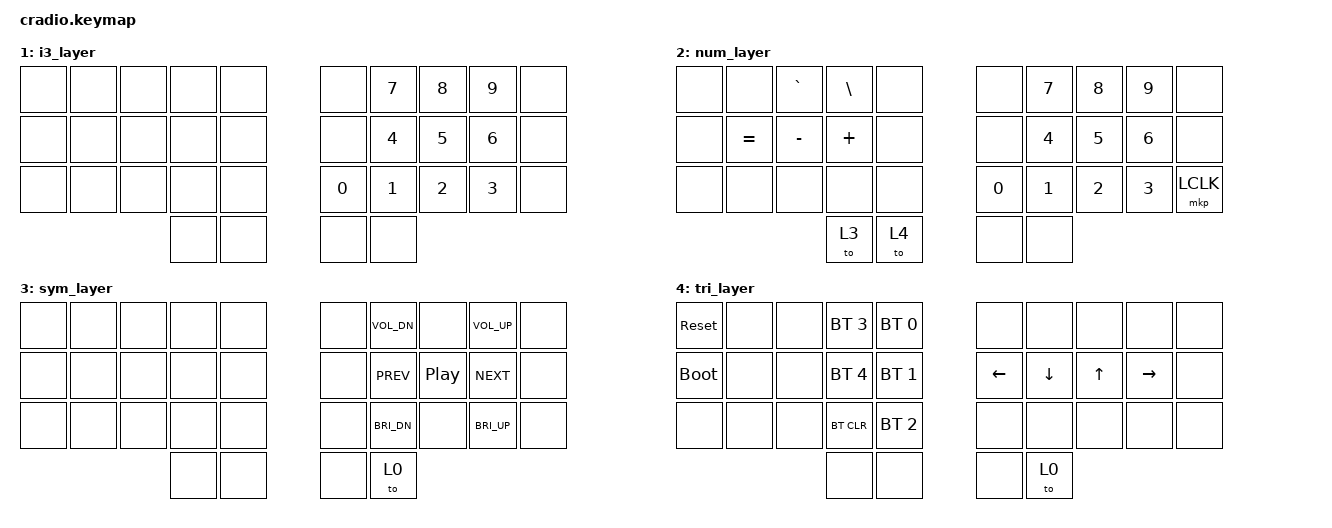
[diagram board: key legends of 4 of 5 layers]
// Copyright (c) 2022 The ZMK Contributors
// SPDX-License-Identifier: MIT

#include <behaviors.dtsi>
#include <dt-bindings/zmk/keys.h>
#include <dt-bindings/zmk/bt.h>
#include <dt-bindings/zmk/pointing.h>

// Home row mods macro
#define HRML(k1,k2,k3,k4) &ht LGUI k1  &ht LALT k2  &ht LSHFT k3  &ht LCTRL k4
#define HRMR(k1,k2,k3,k4) &ht RCTRL k1  &ht RSHFT k2  &ht RALT k3  &ht RGUI k4

/ {
    macros {
        /*
         * Layer-Mod macro:  &lm <layer> <modifier>
         *   – presses &mo <layer>  +  presses &kp <modifier>
         *   – releases both when the macro key is released
         */
        lm: lm {
            compatible = "zmk,behavior-macro-two-param";
            #binding-cells = <2>;
            wait-ms = <0>;
            tap-ms  = <0>;
            bindings =
                <&macro_param_1to1> , <&macro_press   &mo MACRO_PLACEHOLDER>,
                <&macro_param_2to1> , <&macro_press   &kp MACRO_PLACEHOLDER>,
                <&macro_pause_for_release>,
                <&macro_param_2to1> , <&macro_release &kp MACRO_PLACEHOLDER>,
                <&macro_param_1to1> , <&macro_release &mo MACRO_PLACEHOLDER>;
        };
    };

    behaviors {
        ht: hold_tap {
            compatible = "zmk,behavior-hold-tap";
            #binding-cells = <2>;
            flavor = "tap-preferred";
            tapping-term-ms = <200>;
            quick-tap-ms = <150>;
            require-prior-idle-ms = <125>;
            bindings = <&kp>, <&kp>;
        };
    };
    
    combos {
        compatible = "zmk,combos";
        combo_esc {
            timeout-ms = <30>;
          key-positions = <7 8>;
            bindings = <&kp ESC>;
        };
        combo_tab {
            timeout-ms = <30>;
            key-positions = <1 2>;
            bindings = <&kp TAB>;
        };
        combo_paren_l {
            timeout-ms = <30>;
            key-positions = <2 3>;
            bindings = <&kp LPAR>;
        };
        combo_paren_r {
            timeout-ms = <30>;
            key-positions = <6 7>;
            bindings = <&kp RPAR>;
        };
        combo_brac_l {
            timeout-ms = <30>;
            key-positions = <22 23>;
            bindings = <&kp LBRC>;
        };
        combo_brac_r {
            timeout-ms = <30>;
            key-positions = <26 27>;
            bindings = <&kp RBRC>;
        };
        combo_brack_l {
            timeout-ms = <30>;
            key-positions = <12 13>;
            bindings = <&kp LBKT>;
        };
        combo_brack_r {
            timeout-ms = <30>;
            key-positions = <16 17>;
            bindings = <&kp RBKT>;
        };
        combo_enter {
            timeout-ms = <30>;
            key-positions = <5 6>;
            bindings = <&kp ENTER>;
        };
    };
    
    keymap {
        compatible = "zmk,keymap";
        default_layer {
            bindings = <
        //╭──────────┬──────────┬──────────┬──────────┬──────────╮   ╭──────────┬──────────┬──────────┬──────────┬──────────╮
        //│  Z       │ Y        │ O        │ U        │ ; :      │   │  ' "     │  L       │  D       │  W       │  Q       │
            &kp Z      &kp Y      &kp O      &kp U      &kp SEMICOLON  &kp SQT    &kp L      &kp D      &kp W      &kp Q 
        //├──────────┼──────────┼──────────┼──────────┼──────────┤   ├──────────┼──────────┼──────────┼──────────┼──────────┤
        //│  C       │  I       │  E       │  A       │  B       │   │  V       │  H       │  T       │  S       │  N       │
            HRML(C,       I,         E,         A)      &kp B          &kp V      HRMR(H,        T,         S,        N)
        //├──────────┼──────────┼──────────┼──────────┼──────────┤   ├──────────┼──────────┼──────────┼──────────┼──────────┤
        //│  G       │  X       │  J       │  K       │  , <     │   │  . >     │  R       │ M        │ F        │ P        │
            &kp G      &kp X      &kp J      &kp K      &kp COMMA      &kp PERIOD &kp R      &kp M     &kp F      &kp P 
        //╰──────────┴──────────┴──────────┼──────────┼──────────┤   ├──────────┼──────────┼──────────┴──────────┴──────────╯
                                             &lm 1 LGUI &kp BSPC       &kp SPACE  &mo 2  
        //                                 ╰──────────┴──────────╯   ╰──────────┴──────────╯
            >;
        };

        i3_layer {
            bindings = <
        //╭──────────┬──────────┬──────────┬──────────┬──────────╮   ╭──────────┬──────────┬──────────┬──────────┬──────────╮
        //│          │          │          │          │          │   │          │ 7        │ 8        │ 9        │          │
            &none      &none      &none      &none      &none          &none      &kp N7     &kp N8     &kp N9     &none
        //├──────────┼──────────┼──────────┼──────────┼──────────┤   ├──────────┼──────────┼──────────┼──────────┼──────────┤
        //│          │          │          │          │          │   │          │ 4        │ 5        │ 6        │          │
            &none      &none      &none      &none      &none          &none      &kp N4     &kp N5     &kp N6     &none 
        //├──────────┼──────────┼──────────┼──────────┼──────────┤   ├──────────┼──────────┼──────────┼──────────┼──────────┤
        //│          │          │          │          │          │   │          │ 1        │ 2        │ 3        │          │
            &none      &none      &none      &none      &none          &kp N0     &kp N1     &kp N2     &kp N3     &none
        //╰──────────┴──────────┴──────────┼──────────┼──────────┤   ├──────────┼──────────┼──────────┴──────────┴──────────╯
                                             &none      &none          &none      &none
        //                                 ╰──────────┴──────────╯   ╰──────────┴──────────╯
            >;
        };

        num_layer{
            bindings = <
        //╭──────────┬──────────┬──────────┬──────────┬──────────╮   ╭──────────┬──────────┬──────────┬──────────┬──────────╮
        //│          │          │          │          │          │   │          │ 7        │ 8        │ 9        │          │
            &none      &none      &kp GRAVE  &kp BSLH   &none          &none      &kp N7     &kp N8     &kp N9     &none
        //├──────────┼──────────┼──────────┼──────────┼──────────┤   ├──────────┼──────────┼──────────┼──────────┼──────────┤
        //│          │          │          │          │          │   │          │ 4        │ 5        │ 6        │          │
            &none      &kp EQUAL  &kp MINUS  &kp PLUS   &none          &none      &kp N4     &kp N5     &kp N6     &none 
        //├──────────┼──────────┼──────────┼──────────┼──────────┤   ├──────────┼──────────┼──────────┼──────────┼──────────┤
        //│          │          │          │          │          │   │          │ 1        │ 2        │ 3        │          │
            &none      &none      &none      &none      &none          &kp N0     &kp N1     &kp N2     &kp N3     &mkp LCLK
        //╰──────────┴──────────┴──────────┼──────────┼──────────┤   ├──────────┼──────────┼──────────┴──────────┴──────────╯
                                             &to 3      &to 4          &none      &none
        //                                 ╰──────────┴──────────╯   ╰──────────┴──────────╯
            >;
        };

        sym_layer {
            bindings = <
        //╭──────────┬──────────┬──────────┬──────────┬──────────╮   ╭──────────┬──────────┬──────────┬──────────┬──────────╮
        //│          │          │          │          │          │   │          │          │          │          │          │
            &none      &none      &none      &none      &none          &none      &kp C_VOL_DN&none      &kp C_VOL_UP&none
        //├──────────┼──────────┼──────────┼──────────┼──────────┤   ├──────────┼──────────┼──────────┼──────────┼──────────┤
        //│          │          │          │          │          │   │          │          │          │          │          │
            &none      &none      &none      &none      &none          &none      &kp C_PREV &kp C_PP   &kp C_NEXT  &none 
        //├──────────┼──────────┼──────────┼──────────┼──────────┤   ├──────────┼──────────┼──────────┼──────────┼──────────┤
        //│          │          │          │          │          │   │          │          │          │          │          │
            &none      &none      &none      &none      &none          &none      &kp C_BRI_DN&none      &kp C_BRI_UP&none
        //╰──────────┴──────────┴──────────┼──────────┼──────────┤   ├──────────┼──────────┼──────────┴──────────┴──────────╯
                                             &none      &none          &none      &to 0
        //                                 ╰──────────┴──────────╯   ╰──────────┴──────────╯
            >;
        };
        tri_layer {
            bindings = <
        //╭──────────┬──────────┬──────────┬──────────┬──────────╮   ╭──────────┬──────────┬──────────┬──────────┬──────────╮
        //│ RESET    │          │          │          │PROFILE 0 │   │          │          │          │          │          │
           &sys_reset  &none     &none    &bt BT_SEL 3 &bt BT_SEL 0    &none      &none      &none      &none      &none
        //├──────────┼──────────┼──────────┼──────────┼──────────┤   ├──────────┼──────────┼──────────┼──────────┼──────────┤
        //│BOOTLOADER│          │          │          │PROFILE 1 │   │          │          │          │          │          │
          &bootloader  &none     &none    &bt BT_SEL 4 &bt BT_SEL 1    &kp LEFT   &kp DOWN   &kp UP     &kp RIGHT  &none
        //├──────────┼──────────┼──────────┼──────────┼──────────┤   ├──────────┼──────────┼──────────┼──────────┼──────────┤
        //│          │          │          │CLEAR BT  │PROFILE 2 │   │          │          │          │          │          │
            &none      &none     &none      &bt BT_CLR &bt BT_SEL 2    &none      &none      &none      &none      &none
        //╰──────────┴──────────┴──────────┼──────────┼──────────┤   ├──────────┼──────────┼──────────┴──────────┴──────────╯
                                             &none     &none           &none      &to 0
        //                                 ╰──────────┴──────────╯   ╰──────────┴──────────╯
            >;
        };
    };
};
